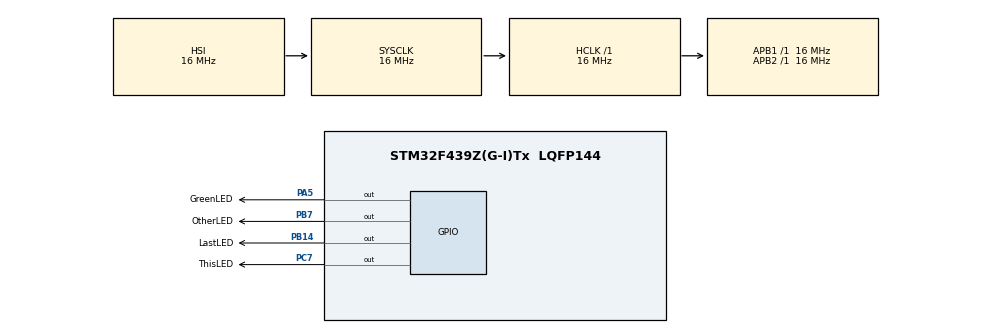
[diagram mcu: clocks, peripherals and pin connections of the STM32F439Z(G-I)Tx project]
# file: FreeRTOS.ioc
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FREERTOS.Tasks01=Task0,24,128,StartDefaultTask,Default,NULL,Dynamic,NULL,NULL;Task1,8,128,StartTask02,Default,NULL,Dynamic,NULL,NULL;Task2,8,128,StartTask03,Default,NULL,Dynamic,NULL,NULL
Mcu.Family=STM32F4
Mcu.Name=STM32F439Z(G-I)Tx
Mcu.Package=LQFP144
NVIC.PriorityGroup=NVIC_PRIORITYGROUP_4
NVIC.TIM6_DAC_IRQn=true\:0\:0\:false\:false\:true\:false\:false\:true
NVIC.TimeBase=TIM6_DAC_IRQn
NVIC.TimeBaseIP=TIM6
PA5.GPIO_Label=GreenLED
PA5.GPIO_ModeDefaultOutputPP=GPIO_MODE_OUTPUT_PP
PA5.GPIO_PuPd=GPIO_NOPULL
PA5.Signal=GPIO_Output
PB14.GPIO_Label=LastLED
PB14.Signal=GPIO_Output
PB7.GPIO_Label=OtherLED
PB7.GPIO_PuPd=GPIO_NOPULL
PB7.Signal=GPIO_Output
PC7.GPIO_Label=ThisLED
PC7.Signal=GPIO_Output
ProjectManager.HeapSize=0x200
ProjectManager.StackSize=0x400
ProjectManager.TargetToolchain=STM32CubeIDE
RCC.AHBFreq_Value=16000000
RCC.APB1Freq_Value=16000000
RCC.APB2Freq_Value=16000000
RCC.CortexFreq_Value=16000000
RCC.HSE_VALUE=25000000
RCC.HSI_VALUE=16000000
RCC.LSE_VALUE=32768
RCC.SYSCLKFreq_VALUE=16000000
RCC.VCOOutputFreq_Value=192000000
VP_FREERTOS_VS_CMSIS_V2.Mode=CMSIS_V2
VP_SYS_VS_tim6.Mode=TIM6
board=custom

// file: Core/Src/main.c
/* USER CODE BEGIN Header */
/**
  ******************************************************************************
  * @file           : main.c
  * @brief          : Main program body
  ******************************************************************************
  * @attention
  *
  * <h2><center>&copy; Copyright (c) 2021 STMicroelectronics.
  * All rights reserved.</center></h2>
  *
  * This software component is licensed by ST under BSD 3-Clause license,
  * the "License"; You may not use this file except in compliance with the
  * License. You may obtain a copy of the License at:
  *                        opensource.org/licenses/BSD-3-Clause
  *
  ******************************************************************************
  */
/* USER CODE END Header */

#include "main.h"
#include "cmsis_os.h"

/* Definitions for Task0 */
osThreadId_t Task0Handle;
const osThreadAttr_t Task0_attributes = {
  .name = "Task0",
  .priority = (osPriority_t) osPriorityNormal,
  .stack_size = 128 * 4
};
/* Definitions for Task1 */
osThreadId_t Task1Handle;
const osThreadAttr_t Task1_attributes = {
  .name = "Task1",
  .priority = (osPriority_t) osPriorityLow,
  .stack_size = 128 * 4
};
/* Definitions for Task2 */
osThreadId_t Task2Handle;
const osThreadAttr_t Task2_attributes = {
  .name = "Task2",
  .priority = (osPriority_t) osPriorityLow,
  .stack_size = 128 * 4
};

void SystemClock_Config(void);
static void MX_GPIO_Init(void);
void StartDefaultTask(void *argument);
void StartTask02(void *argument);
void StartTask03(void *argument);

int main(void)
{

  /* MCU Configuration--------------------------------------------------------*/

  /* Reset of all peripherals, Initializes the Flash interface and the Systick. */
  HAL_Init();

  /* Configure the system clock */
  SystemClock_Config();

  /* Initialize all configured peripherals */
  MX_GPIO_Init();

  /* Init scheduler */
  osKernelInitialize();

  /* Create the thread(s) */
  /* creation of Task0 */
  Task0Handle = osThreadNew(StartDefaultTask, NULL, &Task0_attributes);

  /* creation of Task1 */
  Task1Handle = osThreadNew(StartTask02, NULL, &Task1_attributes);

  /* creation of Task2 */
  Task2Handle = osThreadNew(StartTask03, NULL, &Task2_attributes);

  /* Start scheduler */
  osKernelStart();

  /* We should never get here as control is now taken by the scheduler */
  /* Infinite loop */
  while (1)
  {

  }
}

void SystemClock_Config(void)
{
  RCC_OscInitTypeDef RCC_OscInitStruct = {0};
  RCC_ClkInitTypeDef RCC_ClkInitStruct = {0};

  /** Configure the main internal regulator output voltage
  */
  __HAL_RCC_PWR_CLK_ENABLE();
  __HAL_PWR_VOLTAGESCALING_CONFIG(PWR_REGULATOR_VOLTAGE_SCALE3);
  /** Initializes the CPU, AHB and APB busses clocks
  */
  RCC_OscInitStruct.OscillatorType = RCC_OSCILLATORTYPE_HSI;
  RCC_OscInitStruct.HSIState = RCC_HSI_ON;
  RCC_OscInitStruct.HSICalibrationValue = RCC_HSICALIBRATION_DEFAULT;
  RCC_OscInitStruct.PLL.PLLState = RCC_PLL_NONE;
  if (HAL_RCC_OscConfig(&RCC_OscInitStruct) != HAL_OK)
  {
    Error_Handler();
  }
  /** Initializes the CPU, AHB and APB busses clocks
  */
  RCC_ClkInitStruct.ClockType = RCC_CLOCKTYPE_HCLK|RCC_CLOCKTYPE_SYSCLK
                              |RCC_CLOCKTYPE_PCLK1|RCC_CLOCKTYPE_PCLK2;
  RCC_ClkInitStruct.SYSCLKSource = RCC_SYSCLKSOURCE_HSI;
  RCC_ClkInitStruct.AHBCLKDivider = RCC_SYSCLK_DIV1;
  RCC_ClkInitStruct.APB1CLKDivider = RCC_HCLK_DIV1;
  RCC_ClkInitStruct.APB2CLKDivider = RCC_HCLK_DIV1;

  if (HAL_RCC_ClockConfig(&RCC_ClkInitStruct, FLASH_LATENCY_0) != HAL_OK)
  {
    Error_Handler();
  }
}

static void MX_GPIO_Init(void)
{
  GPIO_InitTypeDef GPIO_InitStruct = {0};

  /* GPIO Ports Clock Enable */
  __HAL_RCC_GPIOA_CLK_ENABLE();
  __HAL_RCC_GPIOB_CLK_ENABLE();
  __HAL_RCC_GPIOC_CLK_ENABLE();

  /*Configure GPIO pin Output Level */
  HAL_GPIO_WritePin(GreenLED_GPIO_Port, GreenLED_Pin, GPIO_PIN_RESET);

  /*Configure GPIO pin Output Level */
  HAL_GPIO_WritePin(GPIOB, LastLED_Pin|OtherLED_Pin, GPIO_PIN_RESET);

  /*Configure GPIO pin Output Level */
  HAL_GPIO_WritePin(ThisLED_GPIO_Port, ThisLED_Pin, GPIO_PIN_RESET);

  /*Configure GPIO pin : GreenLED_Pin */
  GPIO_InitStruct.Pin = GreenLED_Pin;
  GPIO_InitStruct.Mode = GPIO_MODE_OUTPUT_PP;
  GPIO_InitStruct.Pull = GPIO_NOPULL;
  GPIO_InitStruct.Speed = GPIO_SPEED_FREQ_LOW;
  HAL_GPIO_Init(GreenLED_GPIO_Port, &GPIO_InitStruct);

  /*Configure GPIO pins : LastLED_Pin OtherLED_Pin */
  GPIO_InitStruct.Pin = LastLED_Pin|OtherLED_Pin;
  GPIO_InitStruct.Mode = GPIO_MODE_OUTPUT_PP;
  GPIO_InitStruct.Pull = GPIO_NOPULL;
  GPIO_InitStruct.Speed = GPIO_SPEED_FREQ_LOW;
  HAL_GPIO_Init(GPIOB, &GPIO_InitStruct);

  /*Configure GPIO pin : ThisLED_Pin */
  GPIO_InitStruct.Pin = ThisLED_Pin;
  GPIO_InitStruct.Mode = GPIO_MODE_OUTPUT_PP;
  GPIO_InitStruct.Pull = GPIO_NOPULL;
  GPIO_InitStruct.Speed = GPIO_SPEED_FREQ_LOW;
  HAL_GPIO_Init(ThisLED_GPIO_Port, &GPIO_InitStruct);

}

void StartDefaultTask(void *argument)
{
  /* USER CODE BEGIN 5 */
  /* Infinite loop */
  for(;;)
  {
		HAL_GPIO_TogglePin(GPIOB, LD2_Pin);
		osDelay(500);
  }
  /* USER CODE END 5 */
}

void StartTask02(void *argument)
{
  /* USER CODE BEGIN StartTask02 */
  /* Infinite loop */
  for(;;)
  {
	HAL_GPIO_TogglePin(GPIOB, LastLED_Pin);
	HAL_GPIO_TogglePin(GPIOB, OtherLED_Pin);
	osDelay(600);
  }
  /* USER CODE END StartTask02 */
}

void StartTask03(void *argument)
{
  /* USER CODE BEGIN StartTask03 */
  /* Infinite loop */
  for(;;)
  {
		HAL_GPIO_TogglePin(GPIOB, LastLED_Pin);
		osDelay(300);
  }
  /* USER CODE END StartTask03 */
}

 /**
  * @brief  Period elapsed callback in non blocking mode
  * @note   This function is called  when TIM6 interrupt took place, inside
  * HAL_TIM_IRQHandler(). It makes a direct call to HAL_IncTick() to increment
  * a global variable "uwTick" used as application time base.
  * @param  htim : TIM handle
  * @retval None
  */
void HAL_TIM_PeriodElapsedCallback(TIM_HandleTypeDef *htim)
{
  if (htim->Instance == TIM6) {
    HAL_IncTick();
  }
}

void Error_Handler(void)
{
}

/************************ (C) COPYRIGHT STMicroelectronics *****END OF FILE****/
